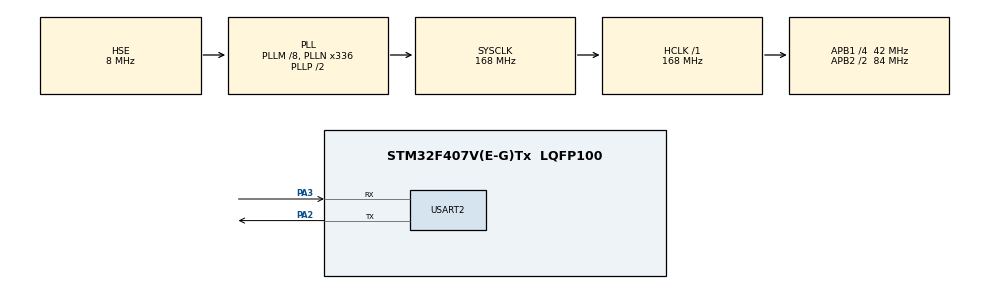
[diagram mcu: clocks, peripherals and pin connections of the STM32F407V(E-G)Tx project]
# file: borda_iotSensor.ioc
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FREERTOS.Tasks01=producer,24,1024,StartProducerTask,Default,NULL,Dynamic,NULL,NULL;consumer,32,1024,StartConsumerTask,Default,NULL,Dynamic,NULL,NULL
Mcu.Family=STM32F4
Mcu.Name=STM32F407V(E-G)Tx
Mcu.Package=LQFP100
NVIC.PriorityGroup=NVIC_PRIORITYGROUP_4
NVIC.TIM1_UP_TIM10_IRQn=true\:15\:0\:false\:false\:true\:false\:false\:true\:true
NVIC.TimeBase=TIM1_UP_TIM10_IRQn
NVIC.TimeBaseIP=TIM1
PA13.GPIO_Label=SWDIO
PA13.Mode=Serial_Wire
PA13.Signal=SYS_JTMS-SWDIO
PA14.GPIO_Label=SWCLK
PA14.Mode=Serial_Wire
PA14.Signal=SYS_JTCK-SWCLK
PA2.Mode=Asynchronous
PA2.Signal=USART2_TX
PA3.Mode=Asynchronous
PA3.Signal=USART2_RX
PB3.GPIO_Label=SWO
PB3.Signal=SYS_JTDO-SWO
PH0-OSC_IN.GPIO_Label=PH0-OSC_IN
PH0-OSC_IN.Mode=HSE-External-Oscillator
PH0-OSC_IN.Signal=RCC_OSC_IN
PH1-OSC_OUT.GPIO_Label=PH1-OSC_OUT
PH1-OSC_OUT.Mode=HSE-External-Oscillator
PH1-OSC_OUT.Signal=RCC_OSC_OUT
ProjectManager.HeapSize=0x200
ProjectManager.StackSize=0x400
ProjectManager.TargetToolchain=STM32CubeIDE
RCC.48MHZClocksFreq_Value=48000000
RCC.AHBFreq_Value=168000000
RCC.APB1CLKDivider=RCC_HCLK_DIV4
RCC.APB1Freq_Value=42000000
RCC.APB1TimFreq_Value=84000000
RCC.APB2CLKDivider=RCC_HCLK_DIV2
RCC.APB2Freq_Value=84000000
RCC.APB2TimFreq_Value=168000000
RCC.CortexFreq_Value=168000000
RCC.HCLKFreq_Value=168000000
RCC.HSE_VALUE=8000000
RCC.HSI_VALUE=16000000
RCC.LSE_VALUE=32768
RCC.PLLM=8
RCC.PLLN=336
RCC.PLLQ=7
RCC.PLLSourceVirtual=RCC_PLLSOURCE_HSE
RCC.SYSCLKFreq_VALUE=168000000
RCC.SYSCLKSource=RCC_SYSCLKSOURCE_PLLCLK
RCC.VCOOutputFreq_Value=336000000
USART2.VirtualMode=VM_ASYNC
VP_FREERTOS_VS_CMSIS_V2.Mode=CMSIS_V2
VP_RTC_VS_RTC_Activate.Mode=RTC_Enabled
VP_SYS_VS_tim1.Mode=TIM1
board=STM32F407G-DISC1

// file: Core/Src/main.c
/* USER CODE BEGIN Header */
/**
  ******************************************************************************
  * @file           : main.c
  * @brief          : Main program body
  ******************************************************************************
  * @attention
  *
  * Copyright (c) 2024 STMicroelectronics.
  * All rights reserved.
  *
  * This software is licensed under terms that can be found in the LICENSE file
  * in the root directory of this software component.
  * If no LICENSE file comes with this software, it is provided AS-IS.
  *
  ******************************************************************************
  */
/* USER CODE END Header */
#include "main.h"
#include "cmsis_os.h"

/* USER CODE BEGIN Includes */
#include "string.h"
#include "stdio.h"
#include "semphr.h"

/* USER LIBRARIES */
#include "transmit.h"
#include "circular_buffer.h"
#include "median_filter.h"
#include "stats.h"
#include "timer.h"
#include "sensors.h"

/* USER CODE END Includes */

/* USER CODE BEGIN PD */
#define OSDELAY_BROADCAST_PERIOD 30000
#define OSDELAY_SAMPLE_PERIOD 1000
/* USER CODE END PD */

 RTC_HandleTypeDef hrtc;

UART_HandleTypeDef huart2;

/* Definitions for producer */
osThreadId_t producerHandle;
const osThreadAttr_t producer_attributes = {
  .name = "producer",
  .stack_size = 1024 * 4,
  .priority = (osPriority_t) osPriorityNormal,
};
/* Definitions for consumer */
osThreadId_t consumerHandle;
const osThreadAttr_t consumer_attributes = {
  .name = "consumer",
  .stack_size = 1024 * 4,
  .priority = (osPriority_t) osPriorityAboveNormal,
};

/* USER CODE BEGIN PV */

/* RTC */
time_handle_t currentTime;

/* SENSOR STRUCTS */
sensor_handle_t sensors[3];

/* MUTEX */
SemaphoreHandle_t mutexData;

/* USER CODE END PV */

void SystemClock_Config(void);
static void MX_GPIO_Init(void);
static void MX_USART2_UART_Init(void);
static void MX_RTC_Init(void);
void StartProducerTask(void *argument);
void StartConsumerTask(void *argument);

int main(void)
{

  /* MCU Configuration--------------------------------------------------------*/

  /* Reset of all peripherals, Initializes the Flash interface and the Systick. */
  HAL_Init();

  /* Configure the system clock */
  SystemClock_Config();

  /* Initialize all configured peripherals */
  MX_GPIO_Init();
  MX_USART2_UART_Init();
  MX_RTC_Init();
  /* USER CODE BEGIN 2 */

  /* INIT RTC */
  timer_init();

  /* INIT SENSORS */
  sensor_init(&sensors[LIGHT], 0x00, "Fake Light Sensor");
  sensor_init(&sensors[TEMP], 0x01, "Fake Temp. Sensor");
  sensor_init(&sensors[CO2], 0x02, "Fake CO_2  Sensor");

  /* INIT MUTEX */
  mutexData = xSemaphoreCreateMutex();

  /* USER CODE END 2 */

  /* Init scheduler */
  osKernelInitialize();

  /* Create the thread(s) */
  /* creation of producer */
  producerHandle = osThreadNew(StartProducerTask, NULL, &producer_attributes);

  /* creation of consumer */
  consumerHandle = osThreadNew(StartConsumerTask, NULL, &consumer_attributes);

  /* Start scheduler */
  osKernelStart();

  /* We should never get here as control is now taken by the scheduler */
  /* Infinite loop */
  while (1)
  {

  }
}

void SystemClock_Config(void)
{
  RCC_OscInitTypeDef RCC_OscInitStruct = {0};
  RCC_ClkInitTypeDef RCC_ClkInitStruct = {0};

  /** Configure the main internal regulator output voltage
  */
  __HAL_RCC_PWR_CLK_ENABLE();
  __HAL_PWR_VOLTAGESCALING_CONFIG(PWR_REGULATOR_VOLTAGE_SCALE1);

  /** Initializes the RCC Oscillators according to the specified parameters
  * in the RCC_OscInitTypeDef structure.
  */
  RCC_OscInitStruct.OscillatorType = RCC_OSCILLATORTYPE_LSI|RCC_OSCILLATORTYPE_HSE;
  RCC_OscInitStruct.HSEState = RCC_HSE_ON;
  RCC_OscInitStruct.LSIState = RCC_LSI_ON;
  RCC_OscInitStruct.PLL.PLLState = RCC_PLL_ON;
  RCC_OscInitStruct.PLL.PLLSource = RCC_PLLSOURCE_HSE;
  RCC_OscInitStruct.PLL.PLLM = 8;
  RCC_OscInitStruct.PLL.PLLN = 336;
  RCC_OscInitStruct.PLL.PLLP = RCC_PLLP_DIV2;
  RCC_OscInitStruct.PLL.PLLQ = 7;
  if (HAL_RCC_OscConfig(&RCC_OscInitStruct) != HAL_OK)
  {
    Error_Handler();
  }

  /** Initializes the CPU, AHB and APB buses clocks
  */
  RCC_ClkInitStruct.ClockType = RCC_CLOCKTYPE_HCLK|RCC_CLOCKTYPE_SYSCLK
                              |RCC_CLOCKTYPE_PCLK1|RCC_CLOCKTYPE_PCLK2;
  RCC_ClkInitStruct.SYSCLKSource = RCC_SYSCLKSOURCE_PLLCLK;
  RCC_ClkInitStruct.AHBCLKDivider = RCC_SYSCLK_DIV1;
  RCC_ClkInitStruct.APB1CLKDivider = RCC_HCLK_DIV4;
  RCC_ClkInitStruct.APB2CLKDivider = RCC_HCLK_DIV2;

  if (HAL_RCC_ClockConfig(&RCC_ClkInitStruct, FLASH_LATENCY_5) != HAL_OK)
  {
    Error_Handler();
  }
}

static void MX_RTC_Init(void)
{

  /** Initialize RTC Only
  */
  hrtc.Instance = RTC;
  hrtc.Init.HourFormat = RTC_HOURFORMAT_24;
  hrtc.Init.AsynchPrediv = 127;
  hrtc.Init.SynchPrediv = 255;
  hrtc.Init.OutPut = RTC_OUTPUT_DISABLE;
  hrtc.Init.OutPutPolarity = RTC_OUTPUT_POLARITY_HIGH;
  hrtc.Init.OutPutType = RTC_OUTPUT_TYPE_OPENDRAIN;
  if (HAL_RTC_Init(&hrtc) != HAL_OK)
  {
    Error_Handler();
  }

}

static void MX_USART2_UART_Init(void)
{

  huart2.Instance = USART2;
  huart2.Init.BaudRate = 9800;
  huart2.Init.WordLength = UART_WORDLENGTH_8B;
  huart2.Init.StopBits = UART_STOPBITS_1;
  huart2.Init.Parity = UART_PARITY_NONE;
  huart2.Init.Mode = UART_MODE_TX_RX;
  huart2.Init.HwFlowCtl = UART_HWCONTROL_NONE;
  huart2.Init.OverSampling = UART_OVERSAMPLING_16;
  if (HAL_UART_Init(&huart2) != HAL_OK)
  {
    Error_Handler();
  }

}

static void MX_GPIO_Init(void)
{

  /* GPIO Ports Clock Enable */
  __HAL_RCC_GPIOH_CLK_ENABLE();
  __HAL_RCC_GPIOA_CLK_ENABLE();
  __HAL_RCC_GPIOB_CLK_ENABLE();

}

void StartProducerTask(void *argument)
{
  /* USER CODE BEGIN 5 */
  /* Infinite loop */
  for(;;)
  {
    osDelay(OSDELAY_SAMPLE_PERIOD);
    if (xSemaphoreTake(mutexData, portMAX_DELAY) == pdTRUE) {

	  /* Sensor Read-Filter-Buffer */
        for (int i = 0; i < LAST_SENSOR; i++) {
            sensor_read(&sensors[i]); // Reads sensor and stores the data in .raw
            buffer_enter_value(&sensors[i].buff_raw, sensors[i].raw);
            filter_sensor_value(&sensors[i].buff_raw, sensors[i].raw, 5, &sensors[i].filtered);
            buffer_enter_value(&sensors[i].buff, sensors[i].filtered);
        }

	  xSemaphoreGive(mutexData);
	  }
  }
  /* USER CODE END 5 */
}

void StartConsumerTask(void *argument)
{
  /* USER CODE BEGIN StartConsumerTask */
  /* Infinite loop */
  for(;;)
  {
    osDelay(OSDELAY_BROADCAST_PERIOD);
    if (xSemaphoreTake(mutexData, portMAX_DELAY) == pdTRUE) {

    	/* RTC */
    	transmit_time(&huart2, &currentTime);

    	/* Calculate and Send Statistics */
    	for (int i = 0; i < LAST_SENSOR; i++) {
    		transmit_stats(&huart2, &sensors[i]);
    	}

		xSemaphoreGive(mutexData);
	}
  }
  /* USER CODE END StartConsumerTask */
}

void HAL_TIM_PeriodElapsedCallback(TIM_HandleTypeDef *htim)
{
  if (htim->Instance == TIM1) {
    HAL_IncTick();
  }
}

void Error_Handler(void)
{
  __disable_irq();
  while (1)
  {
  }
}
